# MCU_j7am_mcu_ecc_aggr0_REGS register map
Vendor: Texas Instruments
Registers are 32-bit, access not given, reset 0x0 unless marked. A register's access mark holds for its fields unless they carry their own. Offsets are as the file gives them; [hi:lo] are bit positions; {n}, {i} and the like mark numbered series.

## MCU_j7am_mcu_ecc_aggr0_REGS (part 2 of 4)
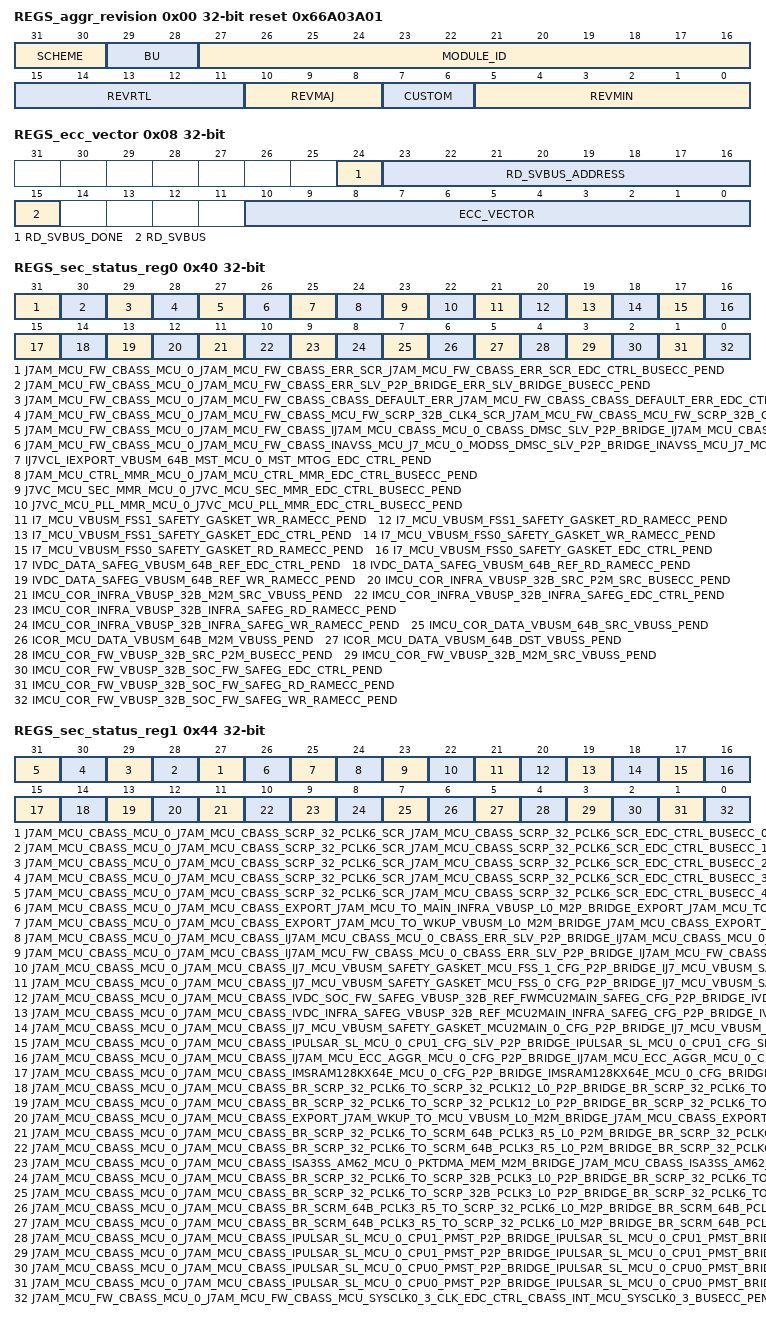
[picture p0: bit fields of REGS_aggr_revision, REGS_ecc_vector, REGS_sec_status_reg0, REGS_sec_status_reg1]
0x00 REGS_aggr_revision ro reset 0x66A03A01 — Revision parameters
  [31:30] SCHEME
  [29:28] BU
  [27:16] MODULE_ID
  [15:11] REVRTL — RTL version
  [10:8] REVMAJ — Major version
  [7:6] CUSTOM — Custom version
  [5:0] REVMIN — Minor version
0x08 REGS_ecc_vector — ECC Vector Register
  [24] RD_SVBUS_DONE — Status to indicate if read on serial VBUS is complete, write of any value will clear this bit. (access R/W1TC)
  [23:16] RD_SVBUS_ADDRESS rw — Read address
  [15] RD_SVBUS — Write 1 to trigger a read on the serial VBUS (access R/W1TS)
  [10:0] ECC_VECTOR rw — Value written to select the corresponding ECC RAM for control or status
0x0C REGS_misc_status ro reset 0x59 — Misc Status
  [10:0] NUM_RAMS — Indicates the number of RAMS serviced by the ECC aggregator
0x10 REGS_reserved_svbus rw — Reference other documents that contain the ECC RAM wrapper and EDC controller serial vbus register sets.
  [31:0] DATA — Serial VBUS register data
0x3C REGS_sec_eoi_reg — EOI Register
  [0] EOI_WR — EOI Register (access R/W1TS)
0x40 REGS_sec_status_reg0 — Interrupt Status Register 0
  [31] J7AM_MCU_FW_CBASS_MCU_0_J7AM_MCU_FW_CBASS_ERR_SCR_J7AM_MCU_FW_CBASS_ERR_SCR_EDC_CTRL_BUSECC_PEND — Interrupt Pending Status for j7am_mcu_fw_cbass_mcu_0_j7am_mcu_fw_cbass_err_scr_j7am_mcu_fw_cbass_err_scr_edc_ctrl_busecc_pend (access R/W1TS)
  [30] J7AM_MCU_FW_CBASS_MCU_0_J7AM_MCU_FW_CBASS_ERR_SLV_P2P_BRIDGE_ERR_SLV_BRIDGE_BUSECC_PEND — Interrupt Pending Status for j7am_mcu_fw_cbass_mcu_0_j7am_mcu_fw_cbass_err_slv_p2p_bridge_err_slv_bridge_busecc_pend (access R/W1TS)
  [29] J7AM_MCU_FW_CBASS_MCU_0_J7AM_MCU_FW_CBASS_CBASS_DEFAULT_ERR_J7AM_MCU_FW_CBASS_CBASS_DEFAULT_ERR_EDC_CTRL_BUSECC_PEND — Interrupt Pending Status for j7am_mcu_fw_cbass_mcu_0_j7am_mcu_fw_cbass_cbass_default_err_j7am_mcu_fw_cbass_cbass_default_err_edc_ctrl_busecc_pend (access R/W1TS)
  [28] J7AM_MCU_FW_CBASS_MCU_0_J7AM_MCU_FW_CBASS_MCU_FW_SCRP_32B_CLK4_SCR_J7AM_MCU_FW_CBASS_MCU_FW_SCRP_32B_CLK4_SCR_EDC_CTRL_BUSECC_PEND — Interrupt Pending Status for j7am_mcu_fw_cbass_mcu_0_j7am_mcu_fw_cbass_MCU_FW_SCRP_32b_CLK4_scr_j7am_mcu_fw_cbass_MCU_FW_SCRP_32b_CLK4_scr_edc_ctrl_busecc_pend (access R/W1TS)
  [27] J7AM_MCU_FW_CBASS_MCU_0_J7AM_MCU_FW_CBASS_IJ7AM_MCU_CBASS_MCU_0_CBASS_DMSC_SLV_P2P_BRIDGE_IJ7AM_MCU_CBASS_MCU_0_CBASS_DMSC_SLV_BRIDGE_BUSECC_PEND — Interrupt Pending Status for j7am_mcu_fw_cbass_mcu_0_j7am_mcu_fw_cbass_Ij7am_mcu_cbass_mcu_0_cbass_dmsc_slv_p2p_bridge_Ij7am_mcu_cbass_mcu_0_cbass_dmsc_slv_bridge_busecc_pend (access R/W1TS)
  [26] J7AM_MCU_FW_CBASS_MCU_0_J7AM_MCU_FW_CBASS_INAVSS_MCU_J7_MCU_0_MODSS_DMSC_SLV_P2P_BRIDGE_INAVSS_MCU_J7_MCU_0_MODSS_DMSC_SLV_BRIDGE_BUSECC_PEND — Interrupt Pending Status for j7am_mcu_fw_cbass_mcu_0_j7am_mcu_fw_cbass_Inavss_mcu_j7_mcu_0_modss_dmsc_slv_p2p_bridge_Inavss_mcu_j7_mcu_0_modss_dmsc_slv_bridge_busecc_pend (access R/W1TS)
  [25] IJ7VCL_IEXPORT_VBUSM_64B_MST_MCU_0_MST_MTOG_EDC_CTRL_PEND — Interrupt Pending Status for Ij7vcl_Iexport_vbusm_64b_mst_mcu_0_mst_mtog_edc_ctrl_pend (access R/W1TS)
  [24] J7AM_MCU_CTRL_MMR_MCU_0_J7AM_MCU_CTRL_MMR_EDC_CTRL_BUSECC_PEND — Interrupt Pending Status for j7am_mcu_ctrl_mmr_mcu_0_j7am_mcu_ctrl_mmr_edc_ctrl_busecc_pend (access R/W1TS)
  [23] J7VC_MCU_SEC_MMR_MCU_0_J7VC_MCU_SEC_MMR_EDC_CTRL_BUSECC_PEND — Interrupt Pending Status for j7vc_mcu_sec_mmr_mcu_0_j7vc_mcu_sec_mmr_edc_ctrl_busecc_pend (access R/W1TS)
  [22] J7VC_MCU_PLL_MMR_MCU_0_J7VC_MCU_PLL_MMR_EDC_CTRL_BUSECC_PEND — Interrupt Pending Status for j7vc_mcu_pll_mmr_mcu_0_j7vc_mcu_pll_mmr_edc_ctrl_busecc_pend (access R/W1TS)
  [21] I7_MCU_VBUSM_FSS1_SAFETY_GASKET_WR_RAMECC_PEND — Interrupt Pending Status for I7_mcu_vbusm_fss1_safety_gasket_wr_ramecc_pend (access R/W1TS)
  [20] I7_MCU_VBUSM_FSS1_SAFETY_GASKET_RD_RAMECC_PEND — Interrupt Pending Status for I7_mcu_vbusm_fss1_safety_gasket_rd_ramecc_pend (access R/W1TS)
  [19] I7_MCU_VBUSM_FSS1_SAFETY_GASKET_EDC_CTRL_PEND — Interrupt Pending Status for I7_mcu_vbusm_fss1_safety_gasket_edc_ctrl_pend (access R/W1TS)
  [18] I7_MCU_VBUSM_FSS0_SAFETY_GASKET_WR_RAMECC_PEND — Interrupt Pending Status for I7_mcu_vbusm_fss0_safety_gasket_wr_ramecc_pend (access R/W1TS)
  [17] I7_MCU_VBUSM_FSS0_SAFETY_GASKET_RD_RAMECC_PEND — Interrupt Pending Status for I7_mcu_vbusm_fss0_safety_gasket_rd_ramecc_pend (access R/W1TS)
  [16] I7_MCU_VBUSM_FSS0_SAFETY_GASKET_EDC_CTRL_PEND — Interrupt Pending Status for I7_mcu_vbusm_fss0_safety_gasket_edc_ctrl_pend (access R/W1TS)
  [15] IVDC_DATA_SAFEG_VBUSM_64B_REF_EDC_CTRL_PEND — Interrupt Pending Status for Ivdc_data_safeg_vbusm_64b_ref_edc_ctrl_pend (access R/W1TS)
  [14] IVDC_DATA_SAFEG_VBUSM_64B_REF_RD_RAMECC_PEND — Interrupt Pending Status for Ivdc_data_safeg_vbusm_64b_ref_rd_ramecc_pend (access R/W1TS)
  [13] IVDC_DATA_SAFEG_VBUSM_64B_REF_WR_RAMECC_PEND — Interrupt Pending Status for Ivdc_data_safeg_vbusm_64b_ref_wr_ramecc_pend (access R/W1TS)
  [12] IMCU_COR_INFRA_VBUSP_32B_SRC_P2M_SRC_BUSECC_PEND — Interrupt Pending Status for Imcu_cor_infra_vbusp_32b_src_p2m_src_busecc_pend (access R/W1TS)
  [11] IMCU_COR_INFRA_VBUSP_32B_M2M_SRC_VBUSS_PEND — Interrupt Pending Status for Imcu_cor_infra_vbusp_32b_m2m_src_vbuss_pend (access R/W1TS)
  [10] IMCU_COR_INFRA_VBUSP_32B_INFRA_SAFEG_EDC_CTRL_PEND — Interrupt Pending Status for Imcu_cor_infra_vbusp_32b_infra_safeg_edc_ctrl_pend (access R/W1TS)
  [9] IMCU_COR_INFRA_VBUSP_32B_INFRA_SAFEG_RD_RAMECC_PEND — Interrupt Pending Status for Imcu_cor_infra_vbusp_32b_infra_safeg_rd_ramecc_pend (access R/W1TS)
  [8] IMCU_COR_INFRA_VBUSP_32B_INFRA_SAFEG_WR_RAMECC_PEND — Interrupt Pending Status for Imcu_cor_infra_vbusp_32b_infra_safeg_wr_ramecc_pend (access R/W1TS)
  [7] IMCU_COR_DATA_VBUSM_64B_SRC_VBUSS_PEND — Interrupt Pending Status for Imcu_cor_data_vbusm_64b_src_vbuss_pend (access R/W1TS)
  [6] ICOR_MCU_DATA_VBUSM_64B_M2M_VBUSS_PEND — Interrupt Pending Status for Icor_mcu_data_vbusm_64b_m2m_vbuss_pend (access R/W1TS)
  [5] ICOR_MCU_DATA_VBUSM_64B_DST_VBUSS_PEND — Interrupt Pending Status for Icor_mcu_data_vbusm_64b_dst_vbuss_pend (access R/W1TS)
  [4] IMCU_COR_FW_VBUSP_32B_SRC_P2M_BUSECC_PEND — Interrupt Pending Status for Imcu_cor_fw_vbusp_32b_src_p2m_busecc_pend (access R/W1TS)
  [3] IMCU_COR_FW_VBUSP_32B_M2M_SRC_VBUSS_PEND — Interrupt Pending Status for Imcu_cor_fw_vbusp_32b_m2m_src_vbuss_pend (access R/W1TS)
  [2] IMCU_COR_FW_VBUSP_32B_SOC_FW_SAFEG_EDC_CTRL_PEND — Interrupt Pending Status for Imcu_cor_fw_vbusp_32b_soc_fw_safeg_edc_ctrl_pend (access R/W1TS)
  [1] IMCU_COR_FW_VBUSP_32B_SOC_FW_SAFEG_RD_RAMECC_PEND — Interrupt Pending Status for Imcu_cor_fw_vbusp_32b_soc_fw_safeg_rd_ramecc_pend (access R/W1TS)
  [0] IMCU_COR_FW_VBUSP_32B_SOC_FW_SAFEG_WR_RAMECC_PEND — Interrupt Pending Status for Imcu_cor_fw_vbusp_32b_soc_fw_safeg_wr_ramecc_pend (access R/W1TS)
0x44 REGS_sec_status_reg1 — Interrupt Status Register 1
  [n+27] J7AM_MCU_CBASS_MCU_0_J7AM_MCU_CBASS_SCRP_32_PCLK6_SCR_J7AM_MCU_CBASS_SCRP_32_PCLK6_SCR_EDC_CTRL_BUSECC_{n}_PEND (n=0..4) — Interrupt Pending Status for j7am_mcu_cbass_mcu_0_j7am_mcu_cbass_SCRP_32_PCLK6_scr_j7am_mcu_cbass_SCRP_32_PCLK6_scr_edc_ctrl_busecc_{n}_pend (access R/W1TS)
  [26] J7AM_MCU_CBASS_MCU_0_J7AM_MCU_CBASS_EXPORT_J7AM_MCU_TO_MAIN_INFRA_VBUSP_L0_M2P_BRIDGE_EXPORT_J7AM_MCU_TO_MAIN_INFRA_VBUSP_L0_BRIDGE_BUSECC_PEND — Interrupt Pending Status for j7am_mcu_cbass_mcu_0_j7am_mcu_cbass_export_j7am_mcu_to_main_infra_vbusp_l0_m2p_bridge_export_j7am_mcu_to_main_infra_vbusp_l0_bridge_busecc_pend (access R/W1TS)
  [25] J7AM_MCU_CBASS_MCU_0_J7AM_MCU_CBASS_EXPORT_J7AM_MCU_TO_WKUP_VBUSM_L0_M2M_BRIDGE_J7AM_MCU_CBASS_EXPORT_J7AM_MCU_TO_WKUP_VBUSM_L0_M2M_BRIDGE_SRC_EDC_CTRL_BUSECC_PEND — Interrupt Pending Status for j7am_mcu_cbass_mcu_0_j7am_mcu_cbass_export_j7am_mcu_to_wkup_vbusm_l0_m2m_bridge_j7am_mcu_cbass_export_j7am_mcu_to_wkup_vbusm_l0_m2m_bridge_src_edc_ctrl_busecc_pend (access R/W1TS)
  [24] J7AM_MCU_CBASS_MCU_0_J7AM_MCU_CBASS_IJ7AM_MCU_CBASS_MCU_0_CBASS_ERR_SLV_P2P_BRIDGE_IJ7AM_MCU_CBASS_MCU_0_CBASS_ERR_SLV_BRIDGE_BUSECC_PEND — Interrupt Pending Status for j7am_mcu_cbass_mcu_0_j7am_mcu_cbass_Ij7am_mcu_cbass_mcu_0_cbass_err_slv_p2p_bridge_Ij7am_mcu_cbass_mcu_0_cbass_err_slv_bridge_busecc_pend (access R/W1TS)
  [23] J7AM_MCU_CBASS_MCU_0_J7AM_MCU_CBASS_IJ7AM_MCU_FW_CBASS_MCU_0_CBASS_ERR_SLV_P2P_BRIDGE_IJ7AM_MCU_FW_CBASS_MCU_0_CBASS_ERR_SLV_BRIDGE_BUSECC_PEND — Interrupt Pending Status for j7am_mcu_cbass_mcu_0_j7am_mcu_cbass_Ij7am_mcu_fw_cbass_mcu_0_cbass_err_slv_p2p_bridge_Ij7am_mcu_fw_cbass_mcu_0_cbass_err_slv_bridge_busecc_pend (access R/W1TS)
  [22] J7AM_MCU_CBASS_MCU_0_J7AM_MCU_CBASS_IJ7_MCU_VBUSM_SAFETY_GASKET_MCU_FSS_1_CFG_P2P_BRIDGE_IJ7_MCU_VBUSM_SAFETY_GASKET_MCU_FSS_1_CFG_BRIDGE_BUSECC_PEND — Interrupt Pending Status for j7am_mcu_cbass_mcu_0_j7am_mcu_cbass_Ij7_mcu_vbusm_safety_gasket_mcu_fss_1_cfg_p2p_bridge_Ij7_mcu_vbusm_safety_gasket_mcu_fss_1_cfg_bridge_busecc_pend (access R/W1TS)
  [21] J7AM_MCU_CBASS_MCU_0_J7AM_MCU_CBASS_IJ7_MCU_VBUSM_SAFETY_GASKET_MCU_FSS_0_CFG_P2P_BRIDGE_IJ7_MCU_VBUSM_SAFETY_GASKET_MCU_FSS_0_CFG_BRIDGE_BUSECC_PEND — Interrupt Pending Status for j7am_mcu_cbass_mcu_0_j7am_mcu_cbass_Ij7_mcu_vbusm_safety_gasket_mcu_fss_0_cfg_p2p_bridge_Ij7_mcu_vbusm_safety_gasket_mcu_fss_0_cfg_bridge_busecc_pend (access R/W1TS)
  [20] J7AM_MCU_CBASS_MCU_0_J7AM_MCU_CBASS_IVDC_SOC_FW_SAFEG_VBUSP_32B_REF_FWMCU2MAIN_SAFEG_CFG_P2P_BRIDGE_IVDC_SOC_FW_SAFEG_VBUSP_32B_REF_FWMCU2MAIN_SAFEG_CFG_BRIDGE_BUSECC_PEND — Interrupt Pending Status for j7am_mcu_cbass_mcu_0_j7am_mcu_cbass_Ivdc_soc_fw_safeg_vbusp_32b_ref_fwmcu2main_safeg_cfg_p2p_bridge_Ivdc_soc_fw_safeg_vbusp_32b_ref_fwmcu2main_safeg_cfg_bridge_busecc_pend (access R/W1TS)
  [19] J7AM_MCU_CBASS_MCU_0_J7AM_MCU_CBASS_IVDC_INFRA_SAFEG_VBUSP_32B_REF_MCU2MAIN_INFRA_SAFEG_CFG_P2P_BRIDGE_IVDC_INFRA_SAFEG_VBUSP_32B_REF_MCU2MAIN_INFRA_SAFEG_CFG_BRIDGE_BUSECC_PEND — Interrupt Pending Status for j7am_mcu_cbass_mcu_0_j7am_mcu_cbass_Ivdc_infra_safeg_vbusp_32b_ref_mcu2main_infra_safeg_cfg_p2p_bridge_Ivdc_infra_safeg_vbusp_32b_ref_mcu2main_infra_safeg_cfg_bridge_busecc_pend (access R/W1TS)
  [18] J7AM_MCU_CBASS_MCU_0_J7AM_MCU_CBASS_IJ7_MCU_VBUSM_SAFETY_GASKET_MCU2MAIN_0_CFG_P2P_BRIDGE_IJ7_MCU_VBUSM_SAFETY_GASKET_MCU2MAIN_0_CFG_BRIDGE_BUSECC_PEND — Interrupt Pending Status for j7am_mcu_cbass_mcu_0_j7am_mcu_cbass_Ij7_mcu_vbusm_safety_gasket_mcu2main_0_cfg_p2p_bridge_Ij7_mcu_vbusm_safety_gasket_mcu2main_0_cfg_bridge_busecc_pend (access R/W1TS)
  [17] J7AM_MCU_CBASS_MCU_0_J7AM_MCU_CBASS_IPULSAR_SL_MCU_0_CPU1_CFG_SLV_P2P_BRIDGE_IPULSAR_SL_MCU_0_CPU1_CFG_SLV_BRIDGE_BUSECC_PEND — Interrupt Pending Status for j7am_mcu_cbass_mcu_0_j7am_mcu_cbass_Ipulsar_sl_mcu_0_cpu1_cfg_slv_p2p_bridge_Ipulsar_sl_mcu_0_cpu1_cfg_slv_bridge_busecc_pend (access R/W1TS)
  [16] J7AM_MCU_CBASS_MCU_0_J7AM_MCU_CBASS_IJ7AM_MCU_ECC_AGGR_MCU_0_CFG_P2P_BRIDGE_IJ7AM_MCU_ECC_AGGR_MCU_0_CFG_BRIDGE_BUSECC_PEND — Interrupt Pending Status for j7am_mcu_cbass_mcu_0_j7am_mcu_cbass_Ij7am_mcu_ecc_aggr_mcu_0_cfg_p2p_bridge_Ij7am_mcu_ecc_aggr_mcu_0_cfg_bridge_busecc_pend (access R/W1TS)
  [15] J7AM_MCU_CBASS_MCU_0_J7AM_MCU_CBASS_IMSRAM128KX64E_MCU_0_CFG_P2P_BRIDGE_IMSRAM128KX64E_MCU_0_CFG_BRIDGE_BUSECC_PEND — Interrupt Pending Status for j7am_mcu_cbass_mcu_0_j7am_mcu_cbass_Imsram128kx64e_mcu_0_cfg_p2p_bridge_Imsram128kx64e_mcu_0_cfg_bridge_busecc_pend (access R/W1TS)
  [14] J7AM_MCU_CBASS_MCU_0_J7AM_MCU_CBASS_BR_SCRP_32_PCLK6_TO_SCRP_32_PCLK12_L0_P2P_BRIDGE_BR_SCRP_32_PCLK6_TO_SCRP_32_PCLK12_L0_BRIDGE_DST_BUSECC_PEND — Interrupt Pending Status for j7am_mcu_cbass_mcu_0_j7am_mcu_cbass_br_SCRP_32_PCLK6_to_SCRP_32_PCLK12_l0_p2p_bridge_br_SCRP_32_PCLK6_to_SCRP_32_PCLK12_l0_bridge_dst_busecc_pend (access R/W1TS)
  [13] J7AM_MCU_CBASS_MCU_0_J7AM_MCU_CBASS_BR_SCRP_32_PCLK6_TO_SCRP_32_PCLK12_L0_P2P_BRIDGE_BR_SCRP_32_PCLK6_TO_SCRP_32_PCLK12_L0_BRIDGE_SRC_BUSECC_PEND — Interrupt Pending Status for j7am_mcu_cbass_mcu_0_j7am_mcu_cbass_br_SCRP_32_PCLK6_to_SCRP_32_PCLK12_l0_p2p_bridge_br_SCRP_32_PCLK6_to_SCRP_32_PCLK12_l0_bridge_src_busecc_pend (access R/W1TS)
  [12] J7AM_MCU_CBASS_MCU_0_J7AM_MCU_CBASS_EXPORT_J7AM_WKUP_TO_MCU_VBUSM_L0_M2M_BRIDGE_J7AM_MCU_CBASS_EXPORT_J7AM_WKUP_TO_MCU_VBUSM_L0_M2M_BRIDGE_SRC_EDC_CTRL_BUSECC_PEND — Interrupt Pending Status for j7am_mcu_cbass_mcu_0_j7am_mcu_cbass_export_j7am_wkup_to_mcu_vbusm_l0_m2m_bridge_j7am_mcu_cbass_export_j7am_wkup_to_mcu_vbusm_l0_m2m_bridge_src_edc_ctrl_busecc_pend (access R/W1TS)
  [11] J7AM_MCU_CBASS_MCU_0_J7AM_MCU_CBASS_BR_SCRP_32_PCLK6_TO_SCRM_64B_PCLK3_R5_L0_P2M_BRIDGE_BR_SCRP_32_PCLK6_TO_SCRM_64B_PCLK3_R5_L0_BRIDGE_DST_BUSECC_PEND — Interrupt Pending Status for j7am_mcu_cbass_mcu_0_j7am_mcu_cbass_br_SCRP_32_PCLK6_to_SCRM_64b_PCLK3_R5_l0_p2m_bridge_br_SCRP_32_PCLK6_to_SCRM_64b_PCLK3_R5_l0_bridge_dst_busecc_pend (access R/W1TS)
  [10] J7AM_MCU_CBASS_MCU_0_J7AM_MCU_CBASS_BR_SCRP_32_PCLK6_TO_SCRM_64B_PCLK3_R5_L0_P2M_BRIDGE_BR_SCRP_32_PCLK6_TO_SCRM_64B_PCLK3_R5_L0_BRIDGE_SRC_BUSECC_PEND — Interrupt Pending Status for j7am_mcu_cbass_mcu_0_j7am_mcu_cbass_br_SCRP_32_PCLK6_to_SCRM_64b_PCLK3_R5_l0_p2m_bridge_br_SCRP_32_PCLK6_to_SCRM_64b_PCLK3_R5_l0_bridge_src_busecc_pend (access R/W1TS)
  [9] J7AM_MCU_CBASS_MCU_0_J7AM_MCU_CBASS_ISA3SS_AM62_MCU_0_PKTDMA_MEM_M2M_BRIDGE_J7AM_MCU_CBASS_ISA3SS_AM62_MCU_0_PKTDMA_MEM_M2M_BRIDGE_SRC_EDC_CTRL_BUSECC_PEND — Interrupt Pending Status for j7am_mcu_cbass_mcu_0_j7am_mcu_cbass_Isa3ss_am62_mcu_0_pktdma_mem_m2m_bridge_j7am_mcu_cbass_Isa3ss_am62_mcu_0_pktdma_mem_m2m_bridge_src_edc_ctrl_busecc_pend (access R/W1TS)
  [8] J7AM_MCU_CBASS_MCU_0_J7AM_MCU_CBASS_BR_SCRP_32_PCLK6_TO_SCRP_32B_PCLK3_L0_P2P_BRIDGE_BR_SCRP_32_PCLK6_TO_SCRP_32B_PCLK3_L0_BRIDGE_DST_BUSECC_PEND — Interrupt Pending Status for j7am_mcu_cbass_mcu_0_j7am_mcu_cbass_br_SCRP_32_PCLK6_to_SCRP_32b_PCLK3_l0_p2p_bridge_br_SCRP_32_PCLK6_to_SCRP_32b_PCLK3_l0_bridge_dst_busecc_pend (access R/W1TS)
  [7] J7AM_MCU_CBASS_MCU_0_J7AM_MCU_CBASS_BR_SCRP_32_PCLK6_TO_SCRP_32B_PCLK3_L0_P2P_BRIDGE_BR_SCRP_32_PCLK6_TO_SCRP_32B_PCLK3_L0_BRIDGE_SRC_BUSECC_PEND — Interrupt Pending Status for j7am_mcu_cbass_mcu_0_j7am_mcu_cbass_br_SCRP_32_PCLK6_to_SCRP_32b_PCLK3_l0_p2p_bridge_br_SCRP_32_PCLK6_to_SCRP_32b_PCLK3_l0_bridge_src_busecc_pend (access R/W1TS)
  [6] J7AM_MCU_CBASS_MCU_0_J7AM_MCU_CBASS_BR_SCRM_64B_PCLK3_R5_TO_SCRP_32_PCLK6_L0_M2P_BRIDGE_BR_SCRM_64B_PCLK3_R5_TO_SCRP_32_PCLK6_L0_BRIDGE_DST_BUSECC_PEND — Interrupt Pending Status for j7am_mcu_cbass_mcu_0_j7am_mcu_cbass_br_SCRM_64b_PCLK3_R5_to_SCRP_32_PCLK6_l0_m2p_bridge_br_SCRM_64b_PCLK3_R5_to_SCRP_32_PCLK6_l0_bridge_dst_busecc_pend (access R/W1TS)
  [5] J7AM_MCU_CBASS_MCU_0_J7AM_MCU_CBASS_BR_SCRM_64B_PCLK3_R5_TO_SCRP_32_PCLK6_L0_M2P_BRIDGE_BR_SCRM_64B_PCLK3_R5_TO_SCRP_32_PCLK6_L0_BRIDGE_SRC_BUSECC_PEND — Interrupt Pending Status for j7am_mcu_cbass_mcu_0_j7am_mcu_cbass_br_SCRM_64b_PCLK3_R5_to_SCRP_32_PCLK6_l0_m2p_bridge_br_SCRM_64b_PCLK3_R5_to_SCRP_32_PCLK6_l0_bridge_src_busecc_pend (access R/W1TS)
  [4] J7AM_MCU_CBASS_MCU_0_J7AM_MCU_CBASS_IPULSAR_SL_MCU_0_CPU1_PMST_P2P_BRIDGE_IPULSAR_SL_MCU_0_CPU1_PMST_BRIDGE_DST_BUSECC_PEND — Interrupt Pending Status for j7am_mcu_cbass_mcu_0_j7am_mcu_cbass_Ipulsar_sl_mcu_0_cpu1_pmst_p2p_bridge_Ipulsar_sl_mcu_0_cpu1_pmst_bridge_dst_busecc_pend (access R/W1TS)
  [3] J7AM_MCU_CBASS_MCU_0_J7AM_MCU_CBASS_IPULSAR_SL_MCU_0_CPU1_PMST_P2P_BRIDGE_IPULSAR_SL_MCU_0_CPU1_PMST_BRIDGE_SRC_BUSECC_PEND — Interrupt Pending Status for j7am_mcu_cbass_mcu_0_j7am_mcu_cbass_Ipulsar_sl_mcu_0_cpu1_pmst_p2p_bridge_Ipulsar_sl_mcu_0_cpu1_pmst_bridge_src_busecc_pend (access R/W1TS)
  [2] J7AM_MCU_CBASS_MCU_0_J7AM_MCU_CBASS_IPULSAR_SL_MCU_0_CPU0_PMST_P2P_BRIDGE_IPULSAR_SL_MCU_0_CPU0_PMST_BRIDGE_DST_BUSECC_PEND — Interrupt Pending Status for j7am_mcu_cbass_mcu_0_j7am_mcu_cbass_Ipulsar_sl_mcu_0_cpu0_pmst_p2p_bridge_Ipulsar_sl_mcu_0_cpu0_pmst_bridge_dst_busecc_pend (access R/W1TS)
  [1] J7AM_MCU_CBASS_MCU_0_J7AM_MCU_CBASS_IPULSAR_SL_MCU_0_CPU0_PMST_P2P_BRIDGE_IPULSAR_SL_MCU_0_CPU0_PMST_BRIDGE_SRC_BUSECC_PEND — Interrupt Pending Status for j7am_mcu_cbass_mcu_0_j7am_mcu_cbass_Ipulsar_sl_mcu_0_cpu0_pmst_p2p_bridge_Ipulsar_sl_mcu_0_cpu0_pmst_bridge_src_busecc_pend (access R/W1TS)
  [0] J7AM_MCU_FW_CBASS_MCU_0_J7AM_MCU_FW_CBASS_MCU_SYSCLK0_3_CLK_EDC_CTRL_CBASS_INT_MCU_SYSCLK0_3_BUSECC_PEND — Interrupt Pending Status for j7am_mcu_fw_cbass_mcu_0_j7am_mcu_fw_cbass_mcu_sysclk0_3_clk_edc_ctrl_cbass_int_mcu_sysclk0_3_busecc_pend (access R/W1TS)
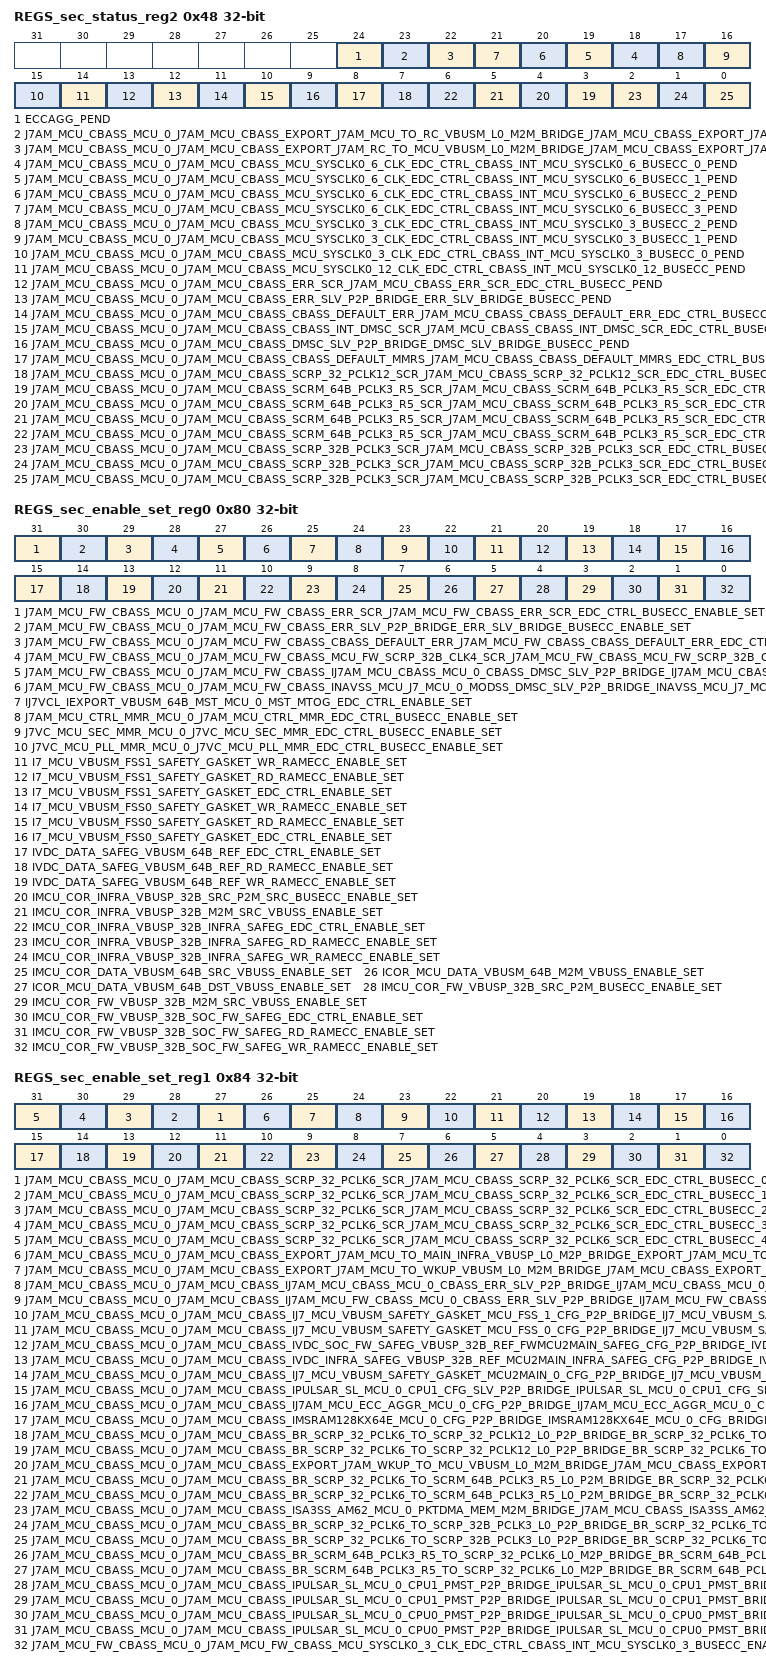
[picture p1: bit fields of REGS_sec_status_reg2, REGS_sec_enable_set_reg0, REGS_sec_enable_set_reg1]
0x48 REGS_sec_status_reg2 — Interrupt Status Register 2
  [24] ECCAGG_PEND — Interrupt Pending Status for eccagg_pend (access R/W1TS)
  [23] J7AM_MCU_CBASS_MCU_0_J7AM_MCU_CBASS_EXPORT_J7AM_MCU_TO_RC_VBUSM_L0_M2M_BRIDGE_J7AM_MCU_CBASS_EXPORT_J7AM_MCU_TO_RC_VBUSM_L0_M2M_BRIDGE_SRC_EDC_CTRL_BUSECC_PEND — Interrupt Pending Status for j7am_mcu_cbass_mcu_0_j7am_mcu_cbass_export_j7am_mcu_to_rc_vbusm_l0_m2m_bridge_j7am_mcu_cbass_export_j7am_mcu_to_rc_vbusm_l0_m2m_bridge_src_edc_ctrl_busecc_pend (access R/W1TS)
  [22] J7AM_MCU_CBASS_MCU_0_J7AM_MCU_CBASS_EXPORT_J7AM_RC_TO_MCU_VBUSM_L0_M2M_BRIDGE_J7AM_MCU_CBASS_EXPORT_J7AM_RC_TO_MCU_VBUSM_L0_M2M_BRIDGE_SRC_EDC_CTRL_BUSECC_PEND — Interrupt Pending Status for j7am_mcu_cbass_mcu_0_j7am_mcu_cbass_export_j7am_rc_to_mcu_vbusm_l0_m2m_bridge_j7am_mcu_cbass_export_j7am_rc_to_mcu_vbusm_l0_m2m_bridge_src_edc_ctrl_busecc_pend (access R/W1TS)
  [n+18] J7AM_MCU_CBASS_MCU_0_J7AM_MCU_CBASS_MCU_SYSCLK0_6_CLK_EDC_CTRL_CBASS_INT_MCU_SYSCLK0_6_BUSECC_{n}_PEND (n=0..3) — Interrupt Pending Status for j7am_mcu_cbass_mcu_0_j7am_mcu_cbass_mcu_sysclk0_6_clk_edc_ctrl_cbass_int_mcu_sysclk0_6_busecc_{n}_pend (access R/W1TS)
  [17] J7AM_MCU_CBASS_MCU_0_J7AM_MCU_CBASS_MCU_SYSCLK0_3_CLK_EDC_CTRL_CBASS_INT_MCU_SYSCLK0_3_BUSECC_2_PEND — Interrupt Pending Status for j7am_mcu_cbass_mcu_0_j7am_mcu_cbass_mcu_sysclk0_3_clk_edc_ctrl_cbass_int_mcu_sysclk0_3_busecc_2_pend (access R/W1TS)
  [16] J7AM_MCU_CBASS_MCU_0_J7AM_MCU_CBASS_MCU_SYSCLK0_3_CLK_EDC_CTRL_CBASS_INT_MCU_SYSCLK0_3_BUSECC_1_PEND — Interrupt Pending Status for j7am_mcu_cbass_mcu_0_j7am_mcu_cbass_mcu_sysclk0_3_clk_edc_ctrl_cbass_int_mcu_sysclk0_3_busecc_1_pend (access R/W1TS)
  [15] J7AM_MCU_CBASS_MCU_0_J7AM_MCU_CBASS_MCU_SYSCLK0_3_CLK_EDC_CTRL_CBASS_INT_MCU_SYSCLK0_3_BUSECC_0_PEND — Interrupt Pending Status for j7am_mcu_cbass_mcu_0_j7am_mcu_cbass_mcu_sysclk0_3_clk_edc_ctrl_cbass_int_mcu_sysclk0_3_busecc_0_pend (access R/W1TS)
  [14] J7AM_MCU_CBASS_MCU_0_J7AM_MCU_CBASS_MCU_SYSCLK0_12_CLK_EDC_CTRL_CBASS_INT_MCU_SYSCLK0_12_BUSECC_PEND — Interrupt Pending Status for j7am_mcu_cbass_mcu_0_j7am_mcu_cbass_mcu_sysclk0_12_clk_edc_ctrl_cbass_int_mcu_sysclk0_12_busecc_pend (access R/W1TS)
  [13] J7AM_MCU_CBASS_MCU_0_J7AM_MCU_CBASS_ERR_SCR_J7AM_MCU_CBASS_ERR_SCR_EDC_CTRL_BUSECC_PEND — Interrupt Pending Status for j7am_mcu_cbass_mcu_0_j7am_mcu_cbass_err_scr_j7am_mcu_cbass_err_scr_edc_ctrl_busecc_pend (access R/W1TS)
  [12] J7AM_MCU_CBASS_MCU_0_J7AM_MCU_CBASS_ERR_SLV_P2P_BRIDGE_ERR_SLV_BRIDGE_BUSECC_PEND — Interrupt Pending Status for j7am_mcu_cbass_mcu_0_j7am_mcu_cbass_err_slv_p2p_bridge_err_slv_bridge_busecc_pend (access R/W1TS)
  [11] J7AM_MCU_CBASS_MCU_0_J7AM_MCU_CBASS_CBASS_DEFAULT_ERR_J7AM_MCU_CBASS_CBASS_DEFAULT_ERR_EDC_CTRL_BUSECC_PEND — Interrupt Pending Status for j7am_mcu_cbass_mcu_0_j7am_mcu_cbass_cbass_default_err_j7am_mcu_cbass_cbass_default_err_edc_ctrl_busecc_pend (access R/W1TS)
  [10] J7AM_MCU_CBASS_MCU_0_J7AM_MCU_CBASS_CBASS_INT_DMSC_SCR_J7AM_MCU_CBASS_CBASS_INT_DMSC_SCR_EDC_CTRL_BUSECC_PEND — Interrupt Pending Status for j7am_mcu_cbass_mcu_0_j7am_mcu_cbass_cbass_int_dmsc_scr_j7am_mcu_cbass_cbass_int_dmsc_scr_edc_ctrl_busecc_pend (access R/W1TS)
  [9] J7AM_MCU_CBASS_MCU_0_J7AM_MCU_CBASS_DMSC_SLV_P2P_BRIDGE_DMSC_SLV_BRIDGE_BUSECC_PEND — Interrupt Pending Status for j7am_mcu_cbass_mcu_0_j7am_mcu_cbass_dmsc_slv_p2p_bridge_dmsc_slv_bridge_busecc_pend (access R/W1TS)
  [8] J7AM_MCU_CBASS_MCU_0_J7AM_MCU_CBASS_CBASS_DEFAULT_MMRS_J7AM_MCU_CBASS_CBASS_DEFAULT_MMRS_EDC_CTRL_BUSECC_PEND — Interrupt Pending Status for j7am_mcu_cbass_mcu_0_j7am_mcu_cbass_cbass_default_mmrs_j7am_mcu_cbass_cbass_default_mmrs_edc_ctrl_busecc_pend (access R/W1TS)
  [7] J7AM_MCU_CBASS_MCU_0_J7AM_MCU_CBASS_SCRP_32_PCLK12_SCR_J7AM_MCU_CBASS_SCRP_32_PCLK12_SCR_EDC_CTRL_BUSECC_PEND — Interrupt Pending Status for j7am_mcu_cbass_mcu_0_j7am_mcu_cbass_SCRP_32_PCLK12_scr_j7am_mcu_cbass_SCRP_32_PCLK12_scr_edc_ctrl_busecc_pend (access R/W1TS)
  [n+3] J7AM_MCU_CBASS_MCU_0_J7AM_MCU_CBASS_SCRM_64B_PCLK3_R5_SCR_J7AM_MCU_CBASS_SCRM_64B_PCLK3_R5_SCR_EDC_CTRL_BUSECC_{n}_PEND (n=0..3) — Interrupt Pending Status for j7am_mcu_cbass_mcu_0_j7am_mcu_cbass_SCRM_64b_PCLK3_R5_scr_j7am_mcu_cbass_SCRM_64b_PCLK3_R5_scr_edc_ctrl_busecc_{n}_pend (access R/W1TS)
  [2] J7AM_MCU_CBASS_MCU_0_J7AM_MCU_CBASS_SCRP_32B_PCLK3_SCR_J7AM_MCU_CBASS_SCRP_32B_PCLK3_SCR_EDC_CTRL_BUSECC_2_PEND — Interrupt Pending Status for j7am_mcu_cbass_mcu_0_j7am_mcu_cbass_SCRP_32b_PCLK3_scr_j7am_mcu_cbass_SCRP_32b_PCLK3_scr_edc_ctrl_busecc_2_pend (access R/W1TS)
  [1] J7AM_MCU_CBASS_MCU_0_J7AM_MCU_CBASS_SCRP_32B_PCLK3_SCR_J7AM_MCU_CBASS_SCRP_32B_PCLK3_SCR_EDC_CTRL_BUSECC_1_PEND — Interrupt Pending Status for j7am_mcu_cbass_mcu_0_j7am_mcu_cbass_SCRP_32b_PCLK3_scr_j7am_mcu_cbass_SCRP_32b_PCLK3_scr_edc_ctrl_busecc_1_pend (access R/W1TS)
  [0] J7AM_MCU_CBASS_MCU_0_J7AM_MCU_CBASS_SCRP_32B_PCLK3_SCR_J7AM_MCU_CBASS_SCRP_32B_PCLK3_SCR_EDC_CTRL_BUSECC_0_PEND — Interrupt Pending Status for j7am_mcu_cbass_mcu_0_j7am_mcu_cbass_SCRP_32b_PCLK3_scr_j7am_mcu_cbass_SCRP_32b_PCLK3_scr_edc_ctrl_busecc_0_pend (access R/W1TS)
0x80 REGS_sec_enable_set_reg0 — Interrupt Enable Set Register 0
  [31] J7AM_MCU_FW_CBASS_MCU_0_J7AM_MCU_FW_CBASS_ERR_SCR_J7AM_MCU_FW_CBASS_ERR_SCR_EDC_CTRL_BUSECC_ENABLE_SET — Interrupt Enable Set Register for j7am_mcu_fw_cbass_mcu_0_j7am_mcu_fw_cbass_err_scr_j7am_mcu_fw_cbass_err_scr_edc_ctrl_busecc_pend (access R/W1TS)
  [30] J7AM_MCU_FW_CBASS_MCU_0_J7AM_MCU_FW_CBASS_ERR_SLV_P2P_BRIDGE_ERR_SLV_BRIDGE_BUSECC_ENABLE_SET — Interrupt Enable Set Register for j7am_mcu_fw_cbass_mcu_0_j7am_mcu_fw_cbass_err_slv_p2p_bridge_err_slv_bridge_busecc_pend (access R/W1TS)
  [29] J7AM_MCU_FW_CBASS_MCU_0_J7AM_MCU_FW_CBASS_CBASS_DEFAULT_ERR_J7AM_MCU_FW_CBASS_CBASS_DEFAULT_ERR_EDC_CTRL_BUSECC_ENABLE_SET — Interrupt Enable Set Register for j7am_mcu_fw_cbass_mcu_0_j7am_mcu_fw_cbass_cbass_default_err_j7am_mcu_fw_cbass_cbass_default_err_edc_ctrl_busecc_pend (access R/W1TS)
  [28] J7AM_MCU_FW_CBASS_MCU_0_J7AM_MCU_FW_CBASS_MCU_FW_SCRP_32B_CLK4_SCR_J7AM_MCU_FW_CBASS_MCU_FW_SCRP_32B_CLK4_SCR_EDC_CTRL_BUSECC_ENABLE_SET — Interrupt Enable Set Register for j7am_mcu_fw_cbass_mcu_0_j7am_mcu_fw_cbass_MCU_FW_SCRP_32b_CLK4_scr_j7am_mcu_fw_cbass_MCU_FW_SCRP_32b_CLK4_scr_edc_ctrl_busecc_pend (access R/W1TS)
  [27] J7AM_MCU_FW_CBASS_MCU_0_J7AM_MCU_FW_CBASS_IJ7AM_MCU_CBASS_MCU_0_CBASS_DMSC_SLV_P2P_BRIDGE_IJ7AM_MCU_CBASS_MCU_0_CBASS_DMSC_SLV_BRIDGE_BUSECC_ENABLE_SET — Interrupt Enable Set Register for j7am_mcu_fw_cbass_mcu_0_j7am_mcu_fw_cbass_Ij7am_mcu_cbass_mcu_0_cbass_dmsc_slv_p2p_bridge_Ij7am_mcu_cbass_mcu_0_cbass_dmsc_slv_bridge_busecc_pend (access R/W1TS)
  [26] J7AM_MCU_FW_CBASS_MCU_0_J7AM_MCU_FW_CBASS_INAVSS_MCU_J7_MCU_0_MODSS_DMSC_SLV_P2P_BRIDGE_INAVSS_MCU_J7_MCU_0_MODSS_DMSC_SLV_BRIDGE_BUSECC_ENABLE_SET — Interrupt Enable Set Register for j7am_mcu_fw_cbass_mcu_0_j7am_mcu_fw_cbass_Inavss_mcu_j7_mcu_0_modss_dmsc_slv_p2p_bridge_Inavss_mcu_j7_mcu_0_modss_dmsc_slv_bridge_busecc_pend (access R/W1TS)
  [25] IJ7VCL_IEXPORT_VBUSM_64B_MST_MCU_0_MST_MTOG_EDC_CTRL_ENABLE_SET — Interrupt Enable Set Register for Ij7vcl_Iexport_vbusm_64b_mst_mcu_0_mst_mtog_edc_ctrl_pend (access R/W1TS)
  [24] J7AM_MCU_CTRL_MMR_MCU_0_J7AM_MCU_CTRL_MMR_EDC_CTRL_BUSECC_ENABLE_SET — Interrupt Enable Set Register for j7am_mcu_ctrl_mmr_mcu_0_j7am_mcu_ctrl_mmr_edc_ctrl_busecc_pend (access R/W1TS)
  [23] J7VC_MCU_SEC_MMR_MCU_0_J7VC_MCU_SEC_MMR_EDC_CTRL_BUSECC_ENABLE_SET — Interrupt Enable Set Register for j7vc_mcu_sec_mmr_mcu_0_j7vc_mcu_sec_mmr_edc_ctrl_busecc_pend (access R/W1TS)
  [22] J7VC_MCU_PLL_MMR_MCU_0_J7VC_MCU_PLL_MMR_EDC_CTRL_BUSECC_ENABLE_SET — Interrupt Enable Set Register for j7vc_mcu_pll_mmr_mcu_0_j7vc_mcu_pll_mmr_edc_ctrl_busecc_pend (access R/W1TS)
  [21] I7_MCU_VBUSM_FSS1_SAFETY_GASKET_WR_RAMECC_ENABLE_SET — Interrupt Enable Set Register for I7_mcu_vbusm_fss1_safety_gasket_wr_ramecc_pend (access R/W1TS)
  [20] I7_MCU_VBUSM_FSS1_SAFETY_GASKET_RD_RAMECC_ENABLE_SET — Interrupt Enable Set Register for I7_mcu_vbusm_fss1_safety_gasket_rd_ramecc_pend (access R/W1TS)
  [19] I7_MCU_VBUSM_FSS1_SAFETY_GASKET_EDC_CTRL_ENABLE_SET — Interrupt Enable Set Register for I7_mcu_vbusm_fss1_safety_gasket_edc_ctrl_pend (access R/W1TS)
  [18] I7_MCU_VBUSM_FSS0_SAFETY_GASKET_WR_RAMECC_ENABLE_SET — Interrupt Enable Set Register for I7_mcu_vbusm_fss0_safety_gasket_wr_ramecc_pend (access R/W1TS)
  [17] I7_MCU_VBUSM_FSS0_SAFETY_GASKET_RD_RAMECC_ENABLE_SET — Interrupt Enable Set Register for I7_mcu_vbusm_fss0_safety_gasket_rd_ramecc_pend (access R/W1TS)
  [16] I7_MCU_VBUSM_FSS0_SAFETY_GASKET_EDC_CTRL_ENABLE_SET — Interrupt Enable Set Register for I7_mcu_vbusm_fss0_safety_gasket_edc_ctrl_pend (access R/W1TS)
  [15] IVDC_DATA_SAFEG_VBUSM_64B_REF_EDC_CTRL_ENABLE_SET — Interrupt Enable Set Register for Ivdc_data_safeg_vbusm_64b_ref_edc_ctrl_pend (access R/W1TS)
  [14] IVDC_DATA_SAFEG_VBUSM_64B_REF_RD_RAMECC_ENABLE_SET — Interrupt Enable Set Register for Ivdc_data_safeg_vbusm_64b_ref_rd_ramecc_pend (access R/W1TS)
  [13] IVDC_DATA_SAFEG_VBUSM_64B_REF_WR_RAMECC_ENABLE_SET — Interrupt Enable Set Register for Ivdc_data_safeg_vbusm_64b_ref_wr_ramecc_pend (access R/W1TS)
  [12] IMCU_COR_INFRA_VBUSP_32B_SRC_P2M_SRC_BUSECC_ENABLE_SET — Interrupt Enable Set Register for Imcu_cor_infra_vbusp_32b_src_p2m_src_busecc_pend (access R/W1TS)
  [11] IMCU_COR_INFRA_VBUSP_32B_M2M_SRC_VBUSS_ENABLE_SET — Interrupt Enable Set Register for Imcu_cor_infra_vbusp_32b_m2m_src_vbuss_pend (access R/W1TS)
  [10] IMCU_COR_INFRA_VBUSP_32B_INFRA_SAFEG_EDC_CTRL_ENABLE_SET — Interrupt Enable Set Register for Imcu_cor_infra_vbusp_32b_infra_safeg_edc_ctrl_pend (access R/W1TS)
  [9] IMCU_COR_INFRA_VBUSP_32B_INFRA_SAFEG_RD_RAMECC_ENABLE_SET — Interrupt Enable Set Register for Imcu_cor_infra_vbusp_32b_infra_safeg_rd_ramecc_pend (access R/W1TS)
  [8] IMCU_COR_INFRA_VBUSP_32B_INFRA_SAFEG_WR_RAMECC_ENABLE_SET — Interrupt Enable Set Register for Imcu_cor_infra_vbusp_32b_infra_safeg_wr_ramecc_pend (access R/W1TS)
  [7] IMCU_COR_DATA_VBUSM_64B_SRC_VBUSS_ENABLE_SET — Interrupt Enable Set Register for Imcu_cor_data_vbusm_64b_src_vbuss_pend (access R/W1TS)
  [6] ICOR_MCU_DATA_VBUSM_64B_M2M_VBUSS_ENABLE_SET — Interrupt Enable Set Register for Icor_mcu_data_vbusm_64b_m2m_vbuss_pend (access R/W1TS)
  [5] ICOR_MCU_DATA_VBUSM_64B_DST_VBUSS_ENABLE_SET — Interrupt Enable Set Register for Icor_mcu_data_vbusm_64b_dst_vbuss_pend (access R/W1TS)
  [4] IMCU_COR_FW_VBUSP_32B_SRC_P2M_BUSECC_ENABLE_SET — Interrupt Enable Set Register for Imcu_cor_fw_vbusp_32b_src_p2m_busecc_pend (access R/W1TS)
  [3] IMCU_COR_FW_VBUSP_32B_M2M_SRC_VBUSS_ENABLE_SET — Interrupt Enable Set Register for Imcu_cor_fw_vbusp_32b_m2m_src_vbuss_pend (access R/W1TS)
  [2] IMCU_COR_FW_VBUSP_32B_SOC_FW_SAFEG_EDC_CTRL_ENABLE_SET — Interrupt Enable Set Register for Imcu_cor_fw_vbusp_32b_soc_fw_safeg_edc_ctrl_pend (access R/W1TS)
  [1] IMCU_COR_FW_VBUSP_32B_SOC_FW_SAFEG_RD_RAMECC_ENABLE_SET — Interrupt Enable Set Register for Imcu_cor_fw_vbusp_32b_soc_fw_safeg_rd_ramecc_pend (access R/W1TS)
  [0] IMCU_COR_FW_VBUSP_32B_SOC_FW_SAFEG_WR_RAMECC_ENABLE_SET — Interrupt Enable Set Register for Imcu_cor_fw_vbusp_32b_soc_fw_safeg_wr_ramecc_pend (access R/W1TS)
0x84 REGS_sec_enable_set_reg1 — Interrupt Enable Set Register 1
  [n+27] J7AM_MCU_CBASS_MCU_0_J7AM_MCU_CBASS_SCRP_32_PCLK6_SCR_J7AM_MCU_CBASS_SCRP_32_PCLK6_SCR_EDC_CTRL_BUSECC_{n}_ENABLE_SET (n=0..4) — Interrupt Enable Set Register for j7am_mcu_cbass_mcu_0_j7am_mcu_cbass_SCRP_32_PCLK6_scr_j7am_mcu_cbass_SCRP_32_PCLK6_scr_edc_ctrl_busecc_{n}_pend (access R/W1TS)
  [26] J7AM_MCU_CBASS_MCU_0_J7AM_MCU_CBASS_EXPORT_J7AM_MCU_TO_MAIN_INFRA_VBUSP_L0_M2P_BRIDGE_EXPORT_J7AM_MCU_TO_MAIN_INFRA_VBUSP_L0_BRIDGE_BUSECC_ENABLE_SET — Interrupt Enable Set Register for j7am_mcu_cbass_mcu_0_j7am_mcu_cbass_export_j7am_mcu_to_main_infra_vbusp_l0_m2p_bridge_export_j7am_mcu_to_main_infra_vbusp_l0_bridge_busecc_pend (access R/W1TS)
  [25] J7AM_MCU_CBASS_MCU_0_J7AM_MCU_CBASS_EXPORT_J7AM_MCU_TO_WKUP_VBUSM_L0_M2M_BRIDGE_J7AM_MCU_CBASS_EXPORT_J7AM_MCU_TO_WKUP_VBUSM_L0_M2M_BRIDGE_SRC_EDC_CTRL_BUSECC_ENABLE_SET — Interrupt Enable Set Register for j7am_mcu_cbass_mcu_0_j7am_mcu_cbass_export_j7am_mcu_to_wkup_vbusm_l0_m2m_bridge_j7am_mcu_cbass_export_j7am_mcu_to_wkup_vbusm_l0_m2m_bridge_src_edc_ctrl_busecc_pend (access R/W1TS)
  [24] J7AM_MCU_CBASS_MCU_0_J7AM_MCU_CBASS_IJ7AM_MCU_CBASS_MCU_0_CBASS_ERR_SLV_P2P_BRIDGE_IJ7AM_MCU_CBASS_MCU_0_CBASS_ERR_SLV_BRIDGE_BUSECC_ENABLE_SET — Interrupt Enable Set Register for j7am_mcu_cbass_mcu_0_j7am_mcu_cbass_Ij7am_mcu_cbass_mcu_0_cbass_err_slv_p2p_bridge_Ij7am_mcu_cbass_mcu_0_cbass_err_slv_bridge_busecc_pend (access R/W1TS)
  [23] J7AM_MCU_CBASS_MCU_0_J7AM_MCU_CBASS_IJ7AM_MCU_FW_CBASS_MCU_0_CBASS_ERR_SLV_P2P_BRIDGE_IJ7AM_MCU_FW_CBASS_MCU_0_CBASS_ERR_SLV_BRIDGE_BUSECC_ENABLE_SET — Interrupt Enable Set Register for j7am_mcu_cbass_mcu_0_j7am_mcu_cbass_Ij7am_mcu_fw_cbass_mcu_0_cbass_err_slv_p2p_bridge_Ij7am_mcu_fw_cbass_mcu_0_cbass_err_slv_bridge_busecc_pend (access R/W1TS)
  [22] J7AM_MCU_CBASS_MCU_0_J7AM_MCU_CBASS_IJ7_MCU_VBUSM_SAFETY_GASKET_MCU_FSS_1_CFG_P2P_BRIDGE_IJ7_MCU_VBUSM_SAFETY_GASKET_MCU_FSS_1_CFG_BRIDGE_BUSECC_ENABLE_SET — Interrupt Enable Set Register for j7am_mcu_cbass_mcu_0_j7am_mcu_cbass_Ij7_mcu_vbusm_safety_gasket_mcu_fss_1_cfg_p2p_bridge_Ij7_mcu_vbusm_safety_gasket_mcu_fss_1_cfg_bridge_busecc_pend (access R/W1TS)
  [21] J7AM_MCU_CBASS_MCU_0_J7AM_MCU_CBASS_IJ7_MCU_VBUSM_SAFETY_GASKET_MCU_FSS_0_CFG_P2P_BRIDGE_IJ7_MCU_VBUSM_SAFETY_GASKET_MCU_FSS_0_CFG_BRIDGE_BUSECC_ENABLE_SET — Interrupt Enable Set Register for j7am_mcu_cbass_mcu_0_j7am_mcu_cbass_Ij7_mcu_vbusm_safety_gasket_mcu_fss_0_cfg_p2p_bridge_Ij7_mcu_vbusm_safety_gasket_mcu_fss_0_cfg_bridge_busecc_pend (access R/W1TS)
  [20] J7AM_MCU_CBASS_MCU_0_J7AM_MCU_CBASS_IVDC_SOC_FW_SAFEG_VBUSP_32B_REF_FWMCU2MAIN_SAFEG_CFG_P2P_BRIDGE_IVDC_SOC_FW_SAFEG_VBUSP_32B_REF_FWMCU2MAIN_SAFEG_CFG_BRIDGE_BUSECC_ENABLE_SET — Interrupt Enable Set Register for j7am_mcu_cbass_mcu_0_j7am_mcu_cbass_Ivdc_soc_fw_safeg_vbusp_32b_ref_fwmcu2main_safeg_cfg_p2p_bridge_Ivdc_soc_fw_safeg_vbusp_32b_ref_fwmcu2main_safeg_cfg_bridge_busecc_pend (access R/W1TS)
  [19] J7AM_MCU_CBASS_MCU_0_J7AM_MCU_CBASS_IVDC_INFRA_SAFEG_VBUSP_32B_REF_MCU2MAIN_INFRA_SAFEG_CFG_P2P_BRIDGE_IVDC_INFRA_SAFEG_VBUSP_32B_REF_MCU2MAIN_INFRA_SAFEG_CFG_BRIDGE_BUSECC_ENABLE_SET — Interrupt Enable Set Register for j7am_mcu_cbass_mcu_0_j7am_mcu_cbass_Ivdc_infra_safeg_vbusp_32b_ref_mcu2main_infra_safeg_cfg_p2p_bridge_Ivdc_infra_safeg_vbusp_32b_ref_mcu2main_infra_safeg_cfg_bridge_busecc_pend (access R/W1TS)
  [18] J7AM_MCU_CBASS_MCU_0_J7AM_MCU_CBASS_IJ7_MCU_VBUSM_SAFETY_GASKET_MCU2MAIN_0_CFG_P2P_BRIDGE_IJ7_MCU_VBUSM_SAFETY_GASKET_MCU2MAIN_0_CFG_BRIDGE_BUSECC_ENABLE_SET — Interrupt Enable Set Register for j7am_mcu_cbass_mcu_0_j7am_mcu_cbass_Ij7_mcu_vbusm_safety_gasket_mcu2main_0_cfg_p2p_bridge_Ij7_mcu_vbusm_safety_gasket_mcu2main_0_cfg_bridge_busecc_pend (access R/W1TS)
  [17] J7AM_MCU_CBASS_MCU_0_J7AM_MCU_CBASS_IPULSAR_SL_MCU_0_CPU1_CFG_SLV_P2P_BRIDGE_IPULSAR_SL_MCU_0_CPU1_CFG_SLV_BRIDGE_BUSECC_ENABLE_SET — Interrupt Enable Set Register for j7am_mcu_cbass_mcu_0_j7am_mcu_cbass_Ipulsar_sl_mcu_0_cpu1_cfg_slv_p2p_bridge_Ipulsar_sl_mcu_0_cpu1_cfg_slv_bridge_busecc_pend (access R/W1TS)
  [16] J7AM_MCU_CBASS_MCU_0_J7AM_MCU_CBASS_IJ7AM_MCU_ECC_AGGR_MCU_0_CFG_P2P_BRIDGE_IJ7AM_MCU_ECC_AGGR_MCU_0_CFG_BRIDGE_BUSECC_ENABLE_SET — Interrupt Enable Set Register for j7am_mcu_cbass_mcu_0_j7am_mcu_cbass_Ij7am_mcu_ecc_aggr_mcu_0_cfg_p2p_bridge_Ij7am_mcu_ecc_aggr_mcu_0_cfg_bridge_busecc_pend (access R/W1TS)
  [15] J7AM_MCU_CBASS_MCU_0_J7AM_MCU_CBASS_IMSRAM128KX64E_MCU_0_CFG_P2P_BRIDGE_IMSRAM128KX64E_MCU_0_CFG_BRIDGE_BUSECC_ENABLE_SET — Interrupt Enable Set Register for j7am_mcu_cbass_mcu_0_j7am_mcu_cbass_Imsram128kx64e_mcu_0_cfg_p2p_bridge_Imsram128kx64e_mcu_0_cfg_bridge_busecc_pend (access R/W1TS)
  [14] J7AM_MCU_CBASS_MCU_0_J7AM_MCU_CBASS_BR_SCRP_32_PCLK6_TO_SCRP_32_PCLK12_L0_P2P_BRIDGE_BR_SCRP_32_PCLK6_TO_SCRP_32_PCLK12_L0_BRIDGE_DST_BUSECC_ENABLE_SET — Interrupt Enable Set Register for j7am_mcu_cbass_mcu_0_j7am_mcu_cbass_br_SCRP_32_PCLK6_to_SCRP_32_PCLK12_l0_p2p_bridge_br_SCRP_32_PCLK6_to_SCRP_32_PCLK12_l0_bridge_dst_busecc_pend (access R/W1TS)
  [13] J7AM_MCU_CBASS_MCU_0_J7AM_MCU_CBASS_BR_SCRP_32_PCLK6_TO_SCRP_32_PCLK12_L0_P2P_BRIDGE_BR_SCRP_32_PCLK6_TO_SCRP_32_PCLK12_L0_BRIDGE_SRC_BUSECC_ENABLE_SET — Interrupt Enable Set Register for j7am_mcu_cbass_mcu_0_j7am_mcu_cbass_br_SCRP_32_PCLK6_to_SCRP_32_PCLK12_l0_p2p_bridge_br_SCRP_32_PCLK6_to_SCRP_32_PCLK12_l0_bridge_src_busecc_pend (access R/W1TS)
  [12] J7AM_MCU_CBASS_MCU_0_J7AM_MCU_CBASS_EXPORT_J7AM_WKUP_TO_MCU_VBUSM_L0_M2M_BRIDGE_J7AM_MCU_CBASS_EXPORT_J7AM_WKUP_TO_MCU_VBUSM_L0_M2M_BRIDGE_SRC_EDC_CTRL_BUSECC_ENABLE_SET — Interrupt Enable Set Register for j7am_mcu_cbass_mcu_0_j7am_mcu_cbass_export_j7am_wkup_to_mcu_vbusm_l0_m2m_bridge_j7am_mcu_cbass_export_j7am_wkup_to_mcu_vbusm_l0_m2m_bridge_src_edc_ctrl_busecc_pend (access R/W1TS)
  [11] J7AM_MCU_CBASS_MCU_0_J7AM_MCU_CBASS_BR_SCRP_32_PCLK6_TO_SCRM_64B_PCLK3_R5_L0_P2M_BRIDGE_BR_SCRP_32_PCLK6_TO_SCRM_64B_PCLK3_R5_L0_BRIDGE_DST_BUSECC_ENABLE_SET — Interrupt Enable Set Register for j7am_mcu_cbass_mcu_0_j7am_mcu_cbass_br_SCRP_32_PCLK6_to_SCRM_64b_PCLK3_R5_l0_p2m_bridge_br_SCRP_32_PCLK6_to_SCRM_64b_PCLK3_R5_l0_bridge_dst_busecc_pend (access R/W1TS)
  [10] J7AM_MCU_CBASS_MCU_0_J7AM_MCU_CBASS_BR_SCRP_32_PCLK6_TO_SCRM_64B_PCLK3_R5_L0_P2M_BRIDGE_BR_SCRP_32_PCLK6_TO_SCRM_64B_PCLK3_R5_L0_BRIDGE_SRC_BUSECC_ENABLE_SET — Interrupt Enable Set Register for j7am_mcu_cbass_mcu_0_j7am_mcu_cbass_br_SCRP_32_PCLK6_to_SCRM_64b_PCLK3_R5_l0_p2m_bridge_br_SCRP_32_PCLK6_to_SCRM_64b_PCLK3_R5_l0_bridge_src_busecc_pend (access R/W1TS)
  [9] J7AM_MCU_CBASS_MCU_0_J7AM_MCU_CBASS_ISA3SS_AM62_MCU_0_PKTDMA_MEM_M2M_BRIDGE_J7AM_MCU_CBASS_ISA3SS_AM62_MCU_0_PKTDMA_MEM_M2M_BRIDGE_SRC_EDC_CTRL_BUSECC_ENABLE_SET — Interrupt Enable Set Register for j7am_mcu_cbass_mcu_0_j7am_mcu_cbass_Isa3ss_am62_mcu_0_pktdma_mem_m2m_bridge_j7am_mcu_cbass_Isa3ss_am62_mcu_0_pktdma_mem_m2m_bridge_src_edc_ctrl_busecc_pend (access R/W1TS)
  [8] J7AM_MCU_CBASS_MCU_0_J7AM_MCU_CBASS_BR_SCRP_32_PCLK6_TO_SCRP_32B_PCLK3_L0_P2P_BRIDGE_BR_SCRP_32_PCLK6_TO_SCRP_32B_PCLK3_L0_BRIDGE_DST_BUSECC_ENABLE_SET — Interrupt Enable Set Register for j7am_mcu_cbass_mcu_0_j7am_mcu_cbass_br_SCRP_32_PCLK6_to_SCRP_32b_PCLK3_l0_p2p_bridge_br_SCRP_32_PCLK6_to_SCRP_32b_PCLK3_l0_bridge_dst_busecc_pend (access R/W1TS)
  [7] J7AM_MCU_CBASS_MCU_0_J7AM_MCU_CBASS_BR_SCRP_32_PCLK6_TO_SCRP_32B_PCLK3_L0_P2P_BRIDGE_BR_SCRP_32_PCLK6_TO_SCRP_32B_PCLK3_L0_BRIDGE_SRC_BUSECC_ENABLE_SET — Interrupt Enable Set Register for j7am_mcu_cbass_mcu_0_j7am_mcu_cbass_br_SCRP_32_PCLK6_to_SCRP_32b_PCLK3_l0_p2p_bridge_br_SCRP_32_PCLK6_to_SCRP_32b_PCLK3_l0_bridge_src_busecc_pend (access R/W1TS)
  [6] J7AM_MCU_CBASS_MCU_0_J7AM_MCU_CBASS_BR_SCRM_64B_PCLK3_R5_TO_SCRP_32_PCLK6_L0_M2P_BRIDGE_BR_SCRM_64B_PCLK3_R5_TO_SCRP_32_PCLK6_L0_BRIDGE_DST_BUSECC_ENABLE_SET — Interrupt Enable Set Register for j7am_mcu_cbass_mcu_0_j7am_mcu_cbass_br_SCRM_64b_PCLK3_R5_to_SCRP_32_PCLK6_l0_m2p_bridge_br_SCRM_64b_PCLK3_R5_to_SCRP_32_PCLK6_l0_bridge_dst_busecc_pend (access R/W1TS)
  [5] J7AM_MCU_CBASS_MCU_0_J7AM_MCU_CBASS_BR_SCRM_64B_PCLK3_R5_TO_SCRP_32_PCLK6_L0_M2P_BRIDGE_BR_SCRM_64B_PCLK3_R5_TO_SCRP_32_PCLK6_L0_BRIDGE_SRC_BUSECC_ENABLE_SET — Interrupt Enable Set Register for j7am_mcu_cbass_mcu_0_j7am_mcu_cbass_br_SCRM_64b_PCLK3_R5_to_SCRP_32_PCLK6_l0_m2p_bridge_br_SCRM_64b_PCLK3_R5_to_SCRP_32_PCLK6_l0_bridge_src_busecc_pend (access R/W1TS)
  [4] J7AM_MCU_CBASS_MCU_0_J7AM_MCU_CBASS_IPULSAR_SL_MCU_0_CPU1_PMST_P2P_BRIDGE_IPULSAR_SL_MCU_0_CPU1_PMST_BRIDGE_DST_BUSECC_ENABLE_SET — Interrupt Enable Set Register for j7am_mcu_cbass_mcu_0_j7am_mcu_cbass_Ipulsar_sl_mcu_0_cpu1_pmst_p2p_bridge_Ipulsar_sl_mcu_0_cpu1_pmst_bridge_dst_busecc_pend (access R/W1TS)
  [3] J7AM_MCU_CBASS_MCU_0_J7AM_MCU_CBASS_IPULSAR_SL_MCU_0_CPU1_PMST_P2P_BRIDGE_IPULSAR_SL_MCU_0_CPU1_PMST_BRIDGE_SRC_BUSECC_ENABLE_SET — Interrupt Enable Set Register for j7am_mcu_cbass_mcu_0_j7am_mcu_cbass_Ipulsar_sl_mcu_0_cpu1_pmst_p2p_bridge_Ipulsar_sl_mcu_0_cpu1_pmst_bridge_src_busecc_pend (access R/W1TS)
  [2] J7AM_MCU_CBASS_MCU_0_J7AM_MCU_CBASS_IPULSAR_SL_MCU_0_CPU0_PMST_P2P_BRIDGE_IPULSAR_SL_MCU_0_CPU0_PMST_BRIDGE_DST_BUSECC_ENABLE_SET — Interrupt Enable Set Register for j7am_mcu_cbass_mcu_0_j7am_mcu_cbass_Ipulsar_sl_mcu_0_cpu0_pmst_p2p_bridge_Ipulsar_sl_mcu_0_cpu0_pmst_bridge_dst_busecc_pend (access R/W1TS)
  [1] J7AM_MCU_CBASS_MCU_0_J7AM_MCU_CBASS_IPULSAR_SL_MCU_0_CPU0_PMST_P2P_BRIDGE_IPULSAR_SL_MCU_0_CPU0_PMST_BRIDGE_SRC_BUSECC_ENABLE_SET — Interrupt Enable Set Register for j7am_mcu_cbass_mcu_0_j7am_mcu_cbass_Ipulsar_sl_mcu_0_cpu0_pmst_p2p_bridge_Ipulsar_sl_mcu_0_cpu0_pmst_bridge_src_busecc_pend (access R/W1TS)
  [0] J7AM_MCU_FW_CBASS_MCU_0_J7AM_MCU_FW_CBASS_MCU_SYSCLK0_3_CLK_EDC_CTRL_CBASS_INT_MCU_SYSCLK0_3_BUSECC_ENABLE_SET — Interrupt Enable Set Register for j7am_mcu_fw_cbass_mcu_0_j7am_mcu_fw_cbass_mcu_sysclk0_3_clk_edc_ctrl_cbass_int_mcu_sysclk0_3_busecc_pend (access R/W1TS)
